# regs-internal register map
Registers are 32-bit, access not given, no defined reset value unless marked. A register's access mark holds for its fields unless they carry their own. Addresses are absolute; registers are grouped by the start of their names; [hi:lo] are bit positions.

## MAC
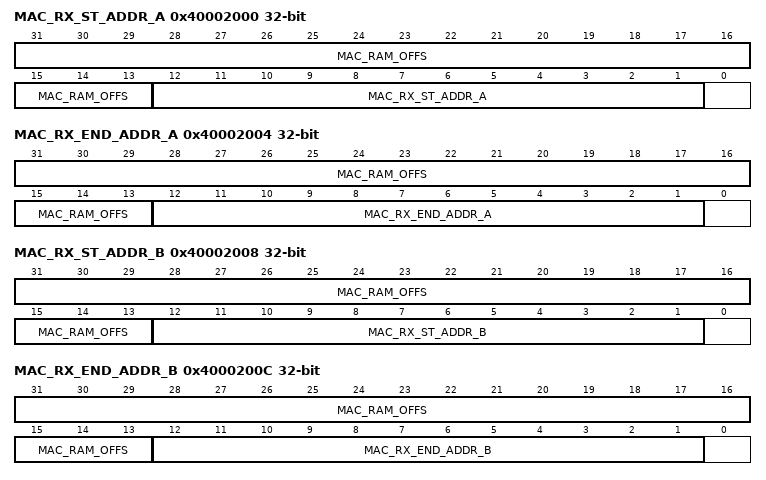
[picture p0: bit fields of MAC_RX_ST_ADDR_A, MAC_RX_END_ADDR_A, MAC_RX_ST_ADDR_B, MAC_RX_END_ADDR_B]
0x40002000 MAC_RX_ST_ADDR_A
  [31:13] MAC_RAM_OFFS, [12:1] MAC_RX_ST_ADDR_A
0x40002004 MAC_RX_END_ADDR_A
  [31:13] MAC_RAM_OFFS, [12:1] MAC_RX_END_ADDR_A
0x40002008 MAC_RX_ST_ADDR_B
  [31:13] MAC_RAM_OFFS, [12:1] MAC_RX_ST_ADDR_B
0x4000200C MAC_RX_END_ADDR_B
  [31:13] MAC_RAM_OFFS, [12:1] MAC_RX_END_ADDR_B
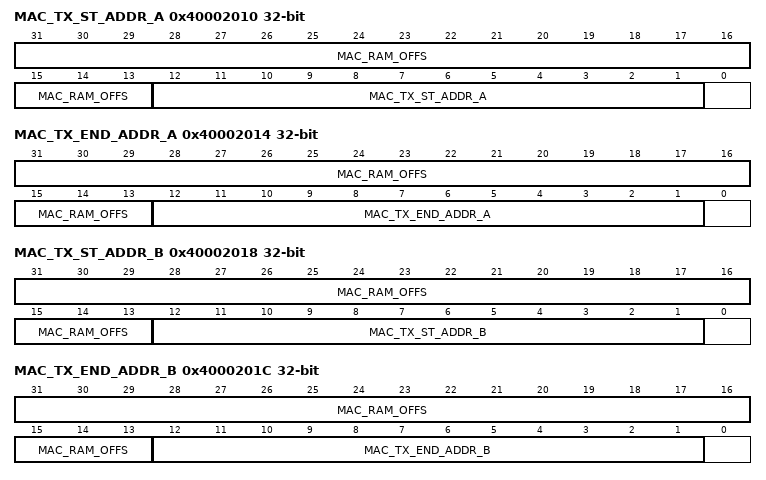
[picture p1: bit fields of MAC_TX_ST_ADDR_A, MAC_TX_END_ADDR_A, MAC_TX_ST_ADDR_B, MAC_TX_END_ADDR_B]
0x40002010 MAC_TX_ST_ADDR_A
  [31:13] MAC_RAM_OFFS, [12:1] MAC_TX_ST_ADDR_A
0x40002014 MAC_TX_END_ADDR_A
  [31:13] MAC_RAM_OFFS, [12:1] MAC_TX_END_ADDR_A
0x40002018 MAC_TX_ST_ADDR_B
  [31:13] MAC_RAM_OFFS, [12:1] MAC_TX_ST_ADDR_B
0x4000201C MAC_TX_END_ADDR_B
  [31:13] MAC_RAM_OFFS, [12:1] MAC_TX_END_ADDR_B
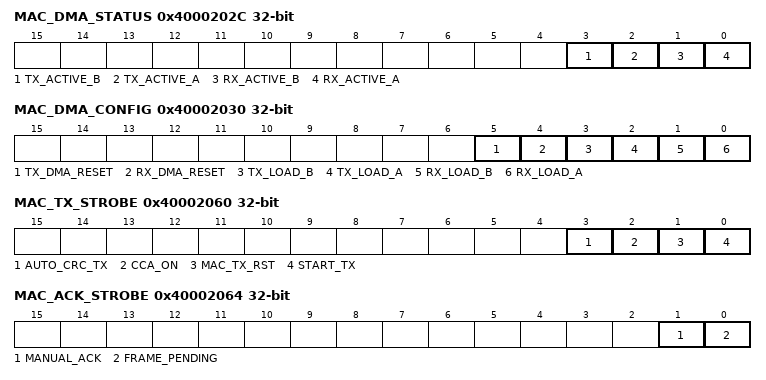
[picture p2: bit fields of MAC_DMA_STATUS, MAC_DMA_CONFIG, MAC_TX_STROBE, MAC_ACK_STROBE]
0x4000202C MAC_DMA_STATUS
  [3] TX_ACTIVE_B, [2] TX_ACTIVE_A, [1] RX_ACTIVE_B, [0] RX_ACTIVE_A
0x40002030 MAC_DMA_CONFIG
  [5] TX_DMA_RESET, [4] RX_DMA_RESET, [3] TX_LOAD_B, [2] TX_LOAD_A, [1] RX_LOAD_B, [0] RX_LOAD_A
0x40002038 MAC_TIMER
  [19:0] MAC_TIMER
0x40002040 MAC_TIMER_COMPARE_A_H
  [3:0] MAC_COMPARE_A_H
0x40002044 MAC_TIMER_COMPARE_A_L
  [15:0] MAC_COMPARE_A_L
0x40002048 MAC_TIMER_COMPARE_B_H
  [3:0] MAC_COMPARE_B_H
0x4000204C MAC_TIMER_COMPARE_B_L
  [15:0] MAC_COMPARE_B_L
0x40002050 MAC_TIMER_CAPTURE_H
  [3:0] MAC_SFD_CAPTURE_HIGH
0x40002054 MAC_TIMER_CAPTURE_L
  [15:0] MAC_SFD_CAPTURE_LOW
0x40002058 MAC_BO_TIMER
  [11:0] MAC_BO_TIMER
0x4000205C MAC_BOP_TIMER
  [6:0] MAC_BOP_TIMER
0x40002060 MAC_TX_STROBE
  [3] AUTO_CRC_TX, [2] CCA_ON, [1] MAC_TX_RST, [0] START_TX
0x40002064 MAC_ACK_STROBE
  [1] MANUAL_ACK, [0] FRAME_PENDING
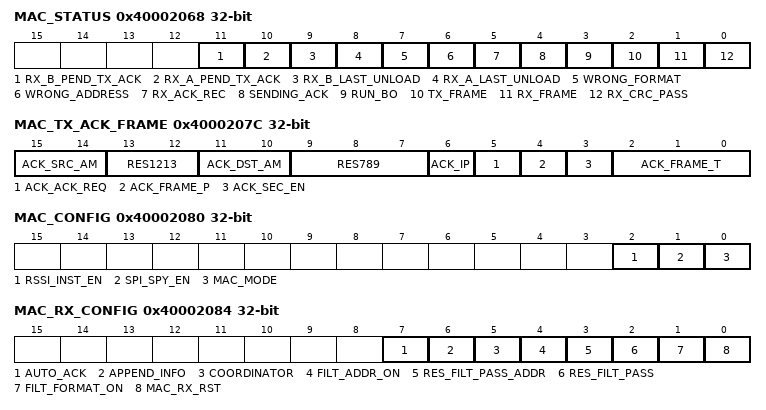
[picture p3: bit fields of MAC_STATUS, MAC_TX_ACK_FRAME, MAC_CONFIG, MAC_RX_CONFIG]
0x40002068 MAC_STATUS
  [11] RX_B_PEND_TX_ACK, [10] RX_A_PEND_TX_ACK, [9] RX_B_LAST_UNLOAD, [8] RX_A_LAST_UNLOAD, [7] WRONG_FORMAT, [6] WRONG_ADDRESS, [5] RX_ACK_REC, [4] SENDING_ACK, [3] RUN_BO, [2] TX_FRAME, [1] RX_FRAME, [0] RX_CRC_PASS
0x40002074 MAC_ACK_TO
  [13:0] ACK_TO
0x40002078 MAC_BOP_COMPARE
  [6:0] MAC_BOP_COMPARE
0x4000207C MAC_TX_ACK_FRAME
  [15:14] ACK_SRC_AM, [13:12] RES1213, [11:10] ACK_DST_AM, [9:7] RES789, [6] ACK_IP, [5] ACK_ACK_REQ, [4] ACK_FRAME_P, [3] ACK_SEC_EN, [2:0] ACK_FRAME_T
0x40002080 MAC_CONFIG
  [2] RSSI_INST_EN, [1] SPI_SPY_EN, [0] MAC_MODE
0x40002084 MAC_RX_CONFIG
  [7] AUTO_ACK, [6] APPEND_INFO, [5] COORDINATOR, [4] FILT_ADDR_ON, [3] RES_FILT_PASS_ADDR, [2] RES_FILT_PASS, [1] FILT_FORMAT_ON, [0] MAC_RX_RST
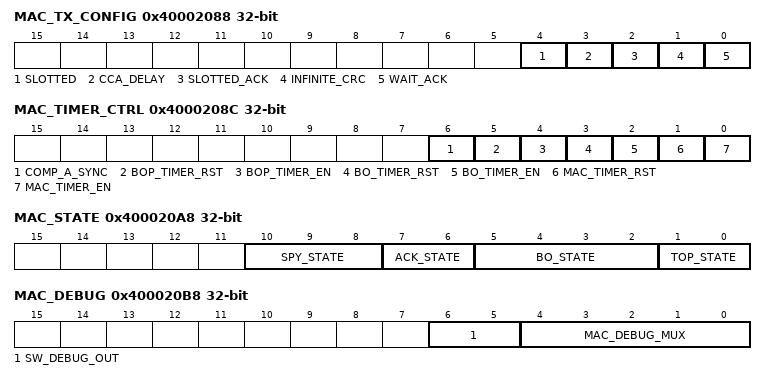
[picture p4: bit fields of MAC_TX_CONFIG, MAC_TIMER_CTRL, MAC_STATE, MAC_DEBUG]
0x40002088 MAC_TX_CONFIG
  [4] SLOTTED, [3] CCA_DELAY, [2] SLOTTED_ACK, [1] INFINITE_CRC, [0] WAIT_ACK
0x4000208C MAC_TIMER_CTRL
  [6] COMP_A_SYNC, [5] BOP_TIMER_RST, [4] BOP_TIMER_EN, [3] BO_TIMER_RST, [2] BO_TIMER_EN, [1] MAC_TIMER_RST, [0] MAC_TIMER_EN
0x400020A8 MAC_STATE
  [10:8] SPY_STATE, [7:6] ACK_STATE, [5:2] BO_STATE, [1:0] TOP_STATE
0x400020B8 MAC_DEBUG
  [6:5] SW_DEBUG_OUT, [4:0] MAC_DEBUG_MUX
0x400020BC MAC_DEBUG_VIEW
  [15:0] MAC_DEBUG_VIEW
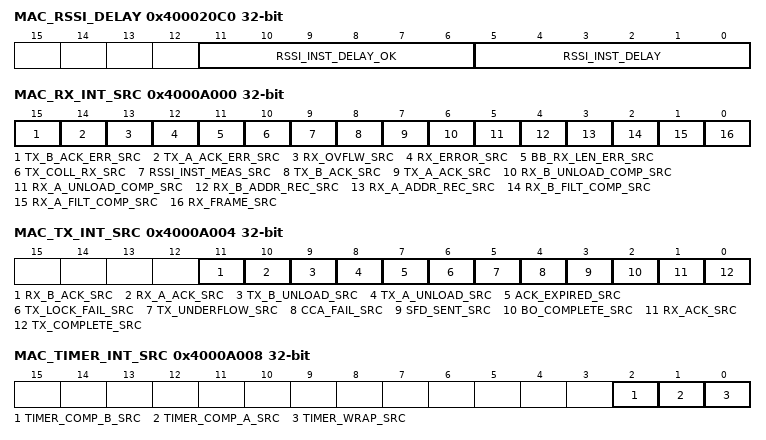
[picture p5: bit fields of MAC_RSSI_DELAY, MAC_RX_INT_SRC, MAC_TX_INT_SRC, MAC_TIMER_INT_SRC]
0x400020C0 MAC_RSSI_DELAY
  [11:6] RSSI_INST_DELAY_OK, [5:0] RSSI_INST_DELAY
0x4000A000 MAC_RX_INT_SRC
  [15] TX_B_ACK_ERR_SRC, [14] TX_A_ACK_ERR_SRC, [13] RX_OVFLW_SRC, [12] RX_ERROR_SRC, [11] BB_RX_LEN_ERR_SRC, [10] TX_COLL_RX_SRC, [9] RSSI_INST_MEAS_SRC, [8] TX_B_ACK_SRC, [7] TX_A_ACK_SRC, [6] RX_B_UNLOAD_COMP_SRC, [5] RX_A_UNLOAD_COMP_SRC, [4] RX_B_ADDR_REC_SRC, [3] RX_A_ADDR_REC_SRC, [2] RX_B_FILT_COMP_SRC, [1] RX_A_FILT_COMP_SRC, [0] RX_FRAME_SRC
0x4000A004 MAC_TX_INT_SRC
  [11] RX_B_ACK_SRC, [10] RX_A_ACK_SRC, [9] TX_B_UNLOAD_SRC, [8] TX_A_UNLOAD_SRC, [7] ACK_EXPIRED_SRC, [6] TX_LOCK_FAIL_SRC, [5] TX_UNDERFLOW_SRC, [4] CCA_FAIL_SRC, [3] SFD_SENT_SRC, [2] BO_COMPLETE_SRC, [1] RX_ACK_SRC, [0] TX_COMPLETE_SRC
0x4000A008 MAC_TIMER_INT_SRC
  [2] TIMER_COMP_B_SRC, [1] TIMER_COMP_A_SRC, [0] TIMER_WRAP_SRC
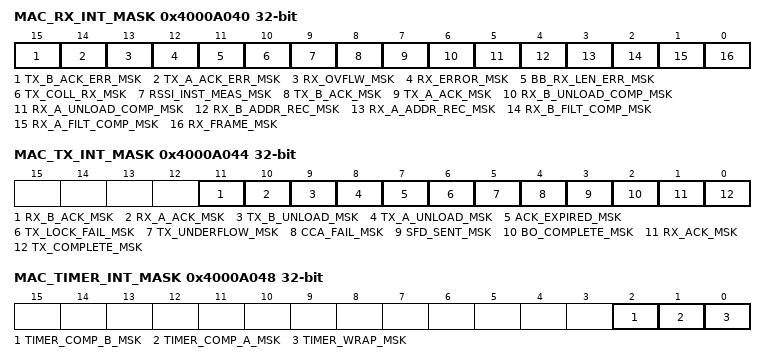
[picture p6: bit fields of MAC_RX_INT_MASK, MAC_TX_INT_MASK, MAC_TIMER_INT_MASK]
0x4000A040 MAC_RX_INT_MASK
  [15] TX_B_ACK_ERR_MSK, [14] TX_A_ACK_ERR_MSK, [13] RX_OVFLW_MSK, [12] RX_ERROR_MSK, [11] BB_RX_LEN_ERR_MSK, [10] TX_COLL_RX_MSK, [9] RSSI_INST_MEAS_MSK, [8] TX_B_ACK_MSK, [7] TX_A_ACK_MSK, [6] RX_B_UNLOAD_COMP_MSK, [5] RX_A_UNLOAD_COMP_MSK, [4] RX_B_ADDR_REC_MSK, [3] RX_A_ADDR_REC_MSK, [2] RX_B_FILT_COMP_MSK, [1] RX_A_FILT_COMP_MSK, [0] RX_FRAME_MSK
0x4000A044 MAC_TX_INT_MASK
  [11] RX_B_ACK_MSK, [10] RX_A_ACK_MSK, [9] TX_B_UNLOAD_MSK, [8] TX_A_UNLOAD_MSK, [7] ACK_EXPIRED_MSK, [6] TX_LOCK_FAIL_MSK, [5] TX_UNDERFLOW_MSK, [4] CCA_FAIL_MSK, [3] SFD_SENT_MSK, [2] BO_COMPLETE_MSK, [1] RX_ACK_MSK, [0] TX_COMPLETE_MSK
0x4000A048 MAC_TIMER_INT_MASK
  [2] TIMER_COMP_B_MSK, [1] TIMER_COMP_A_MSK, [0] TIMER_WRAP_MSK
